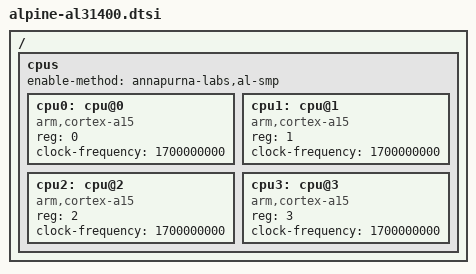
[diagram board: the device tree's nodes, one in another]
// SPDX-License-Identifier: GPL-2.0-or-later OR MIT

#include "alpine-generic.dtsi"

/ {
	cpus {
		#address-cells = <1>;
		#size-cells = <0>;
		enable-method = "annapurna-labs,al-smp";

		cpu0: cpu@0 {
			compatible = "arm,cortex-a15";
			device_type = "cpu";
			reg = <0>;
			clock-frequency = <1700000000>;
		};

		cpu1: cpu@1 {
			compatible = "arm,cortex-a15";
			device_type = "cpu";
			reg = <1>;
			clock-frequency = <1700000000>;
		};

		cpu2: cpu@2 {
			compatible = "arm,cortex-a15";
			device_type = "cpu";
			reg = <2>;
			clock-frequency = <1700000000>;
		};

		cpu3: cpu@3 {
			compatible = "arm,cortex-a15";
			device_type = "cpu";
			reg = <3>;
			clock-frequency = <1700000000>;
		};
	};
};
